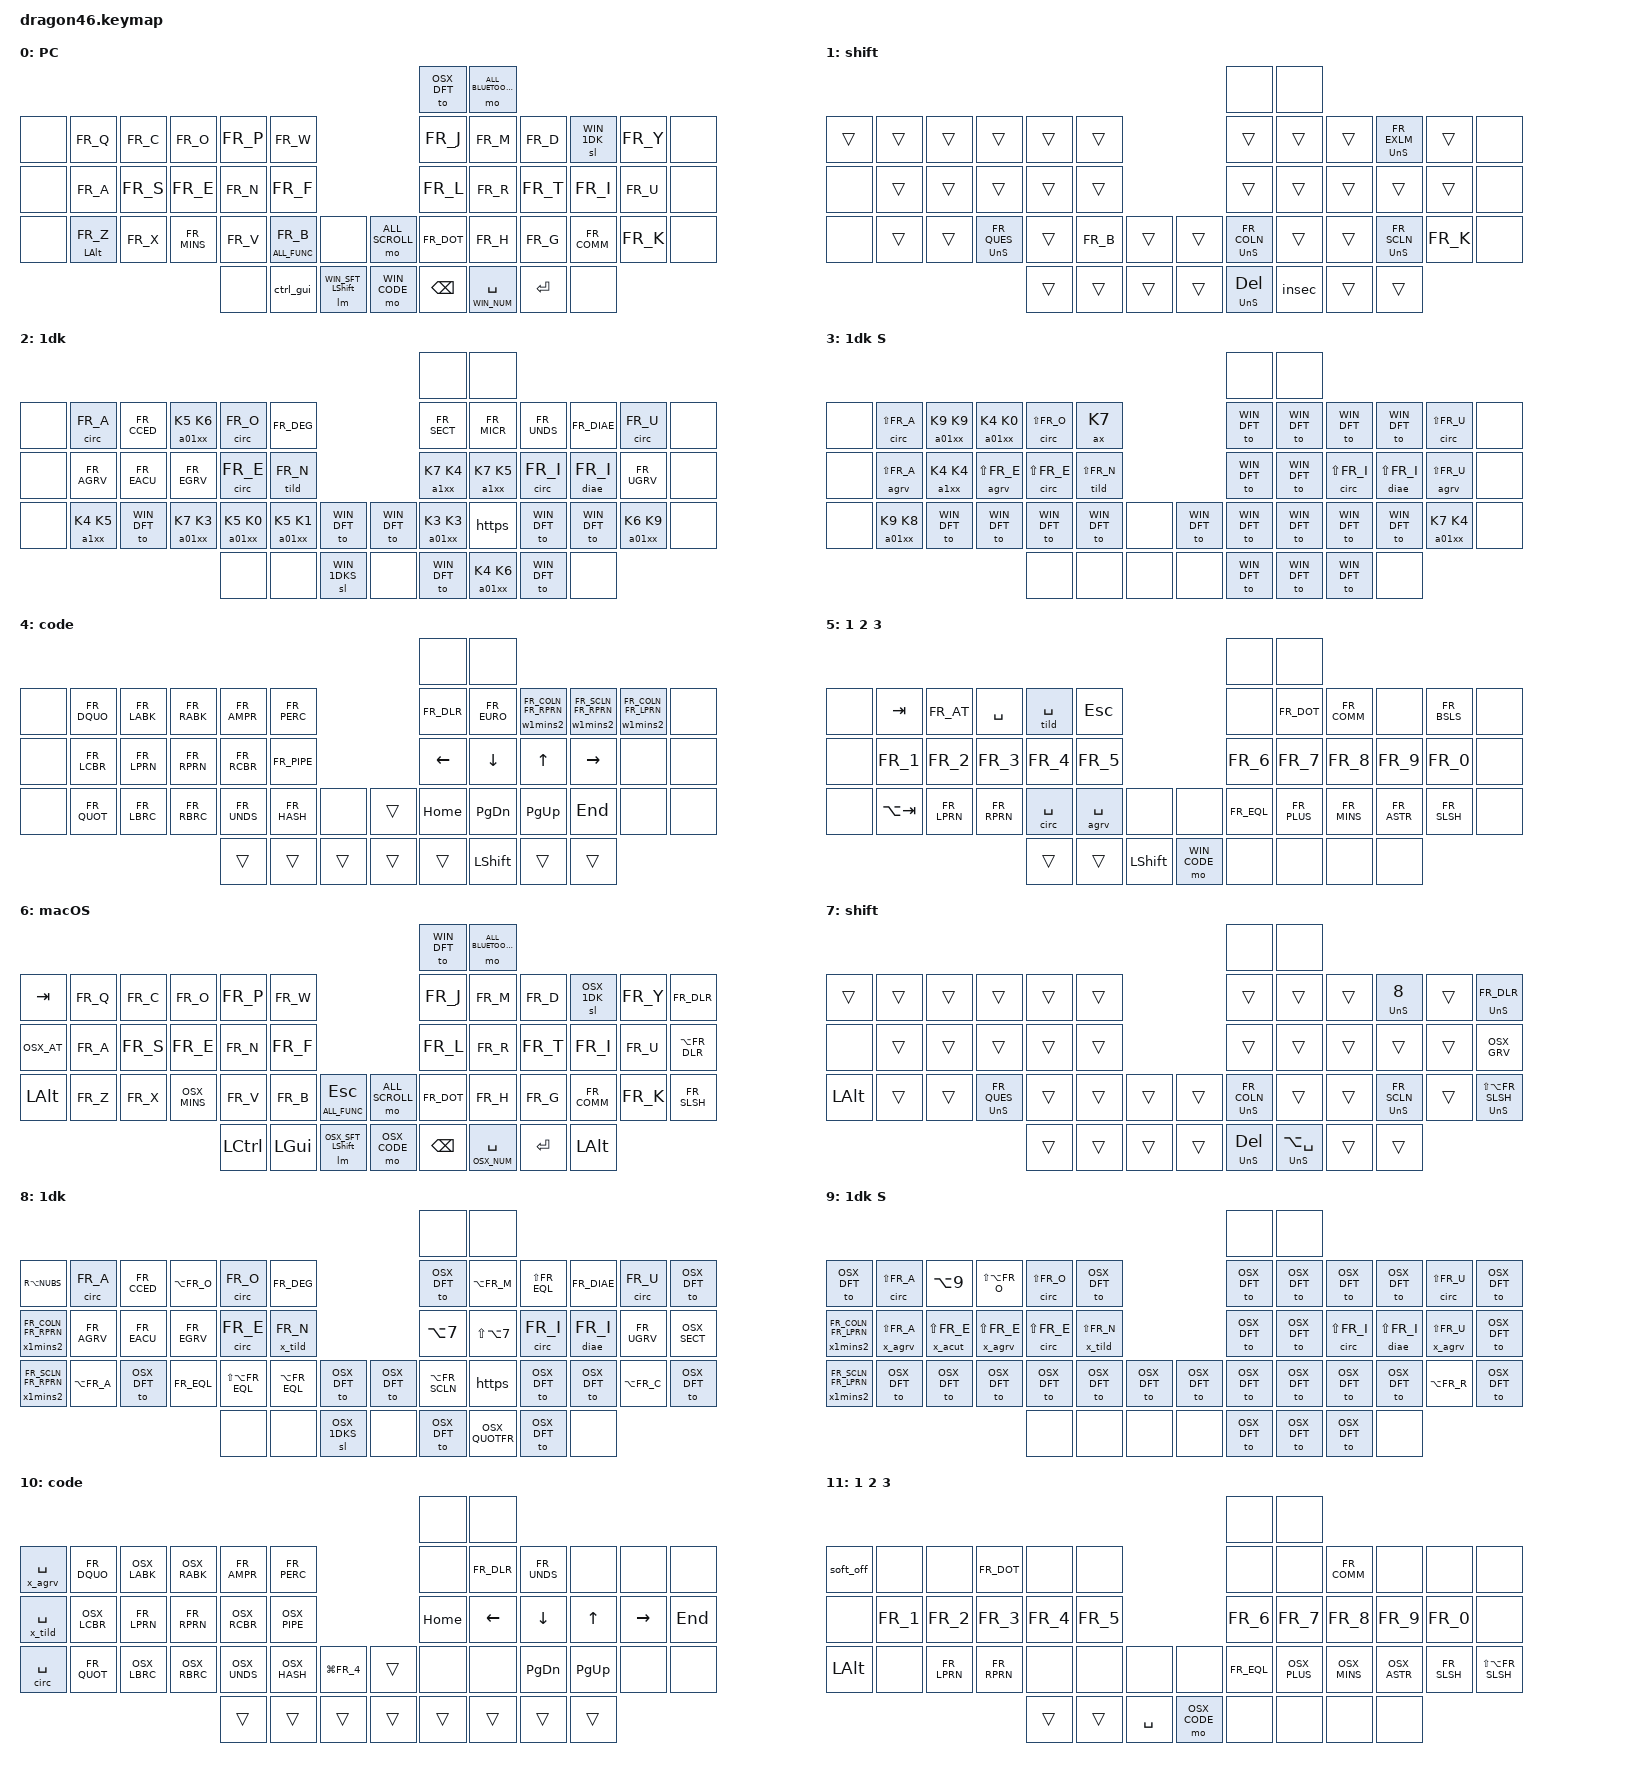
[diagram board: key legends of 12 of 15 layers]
/*
 * Copyright (c) 2021 The ZMK Contributors
 *
 * SPDX-License-Identifier: MIT
 */

 /* COMPIL:
west build -b nice_nano_v2 -- -DSHIELD="dragon46 nice_view_adapter nice_view" 
 */

#include <behaviors.dtsi>
#include <dt-bindings/zmk/keys.h>
#include <dt-bindings/zmk/bt.h>
#include <dt-bindings/zmk/outputs.h>
#include <dt-bindings/zmk/ext_power.h>
#include "keymap_french.h"

#define WIN_DFT         0
#define WIN_SFT         1
#define WIN_1DK         2
#define WIN_1DKS        3
#define WIN_CODE        4
#define WIN_NUM         5

#define OSX_DFT         6
#define OSX_SFT         7
#define OSX_1DK         8
#define OSX_1DKS        9
#define OSX_CODE        10
#define OSX_NUM         11

#define ALL_FUNC        12
#define ALL_SCROLL      13
#define ALL_BLUETOOTH   14

#define K0 KP_N0
#define K1 KP_N1
#define K2 KP_N2
#define K3 KP_N3
#define K4 KP_N4
#define K5 KP_N5
#define K6 KP_N6
#define K7 KP_N7
#define K8 KP_N8
#define K9 KP_N9 

&sl {
    release-after-ms = <2000>;
};

/ {

    macros {
        lm: lm {
            compatible = "zmk,behavior-macro-two-param";
            wait-ms = <0>;
            tap-ms = <0>;
            #binding-cells = <2>;
            bindings
                = <&macro_param_1to1>
                , <&macro_press &mo MACRO_PLACEHOLDER>
                , <&macro_param_2to1>
                , <&macro_press &kp MACRO_PLACEHOLDER>
                , <&macro_pause_for_release>
                , <&macro_param_2to1>
                , <&macro_release &kp MACRO_PLACEHOLDER>
                , <&macro_param_1to1>
                , <&macro_release &mo MACRO_PLACEHOLDER>
                ;
        };

        ctrl_gui: tap_dance_mod_tap {
            compatible = "zmk,behavior-tap-dance";
            #binding-cells = <0>;
            tapping-term-ms = <200>;
            bindings = <&kp LCTRL>, <&kp LGUI>;
        };

        UnS: UnS {
            compatible = "zmk,behavior-macro-one-param";
            #binding-cells = <1>;
            bindings = 
                <&macro_release &kp LSHFT>
                ,<&macro_param_1to1>,<&macro_tap &kp MACRO_PLACEHOLDER>
                ,<&macro_press &kp LSHFT>;
        };

        circ: circ {
            compatible = "zmk,behavior-macro-one-param";
            #binding-cells = <1>;
            wait-ms = <20>;
            tap-ms = <20>;
            bindings = 
                <&macro_tap &kp FR_CIRC>
                ,<&macro_param_1to1>,<&macro_tap &kp MACRO_PLACEHOLDER>;
        };

        tild: tild {
            compatible = "zmk,behavior-macro-one-param";
            #binding-cells = <1>;
            wait-ms = <20>;
            tap-ms = <20>;
            bindings = 
                <&macro_tap &kp FR_TILD>
                ,<&macro_param_1to1>,<&macro_tap &kp MACRO_PLACEHOLDER>;
        };

        x_tild: x_tild {
            compatible = "zmk,behavior-macro-one-param";
            #binding-cells = <1>;
            wait-ms = <20>;
            tap-ms = <20>;
            bindings = 
                <&macro_tap &kp LA(FR_N)>
                ,<&macro_param_1to1>,<&macro_tap &kp MACRO_PLACEHOLDER>;
        };

        diae: diae {
            compatible = "zmk,behavior-macro-one-param";
            #binding-cells = <1>;
            wait-ms = <20>; tap-ms = <20>;
            bindings = 
                <&macro_tap &kp LS(FR_CIRC)>
                ,<&macro_param_1to1>,<&macro_tap &kp MACRO_PLACEHOLDER>;
        };

        caps: caps {
            compatible = "zmk,behavior-macro-one-param";
            #binding-cells = <1>;
            wait-ms = <40>; tap-ms = <40>;
            bindings = 
                <&macro_tap &kp CAPS>
                ,<&macro_param_1to1>,<&macro_tap &kp MACRO_PLACEHOLDER>
                ,<&macro_tap &kp CAPS>;
        };

        x_acut: x_acut {
            compatible = "zmk,behavior-macro-one-param";
            #binding-cells = <1>;
            wait-ms = <20>; tap-ms = <20>;
            bindings = 
                <&macro_tap &kp LS(LA(N1))>
                ,<&macro_param_1to1>,<&macro_tap &kp MACRO_PLACEHOLDER>;
        };

        x_agrv: x_agrv {
            compatible = "zmk,behavior-macro-one-param";
            #binding-cells = <1>;
            wait-ms = <20>; tap-ms = <20>;
            bindings = 
                <&macro_tap &kp OSX_GRV>
                ,<&macro_param_1to1>,<&macro_tap &kp MACRO_PLACEHOLDER>;
        };

        agrv: agrv {
            compatible = "zmk,behavior-macro-one-param";
            #binding-cells = <1>;
            wait-ms = <20>; tap-ms = <20>;
            bindings = 
                <&macro_tap &kp FR_GRV>
                ,<&macro_param_1to1>,<&macro_tap &kp MACRO_PLACEHOLDER>;
        };

        ax: ax {
            compatible = "zmk,behavior-macro-one-param";
            #binding-cells = <1>;
            wait-ms = <20>; tap-ms = <20>;
            bindings = 
                <&macro_press &kp LALT>
                ,<&macro_param_1to1>,<&macro_tap &kp MACRO_PLACEHOLDER>
                ,<&macro_release &kp LALT>;
        };

        a1xx: a1xx {
            compatible = "zmk,behavior-macro-two-param";
            #binding-cells = <2>;
            wait-ms = <20>; tap-ms = <20>;
            bindings = 
                <&macro_press &kp LALT>
                ,<&macro_tap &kp KP_N1>
                ,<&macro_param_1to1>,<&macro_tap &kp MACRO_PLACEHOLDER>
                ,<&macro_param_2to1>,<&macro_tap &kp MACRO_PLACEHOLDER>
                ,<&macro_release &kp LALT>;
        };

        a2xx: a2xx {
            compatible = "zmk,behavior-macro-two-param";
            #binding-cells = <2>;
            wait-ms = <20>; tap-ms = <20>;
            bindings = 
                <&macro_press &kp LALT>
                ,<&macro_tap &kp KP_N2>
                ,<&macro_param_1to1>,<&macro_tap &kp MACRO_PLACEHOLDER>
                ,<&macro_param_2to1>,<&macro_tap &kp MACRO_PLACEHOLDER>
                ,<&macro_release &kp LALT>;
        };

        a01xx: a01xx {
            compatible = "zmk,behavior-macro-two-param";
            #binding-cells = <2>;
            wait-ms = <10>; tap-ms = <10>;
            bindings = 
                <&macro_press &kp LALT>
                ,<&macro_tap &kp KP_N0>
                ,<&macro_tap &kp KP_N1>
                ,<&macro_param_1to1>,<&macro_tap &kp MACRO_PLACEHOLDER>
                ,<&macro_param_2to1>,<&macro_tap &kp MACRO_PLACEHOLDER>
                ,<&macro_release &kp LALT>;
        };

        insec: insec {
            compatible = "zmk,behavior-macro";
            #binding-cells = <0>;
            wait-ms = <20>; tap-ms = <20>;
            bindings = 
                <&macro_release &kp LSHFT>
                ,<&macro_press &kp LALT>
                ,<&macro_tap &kp KP_N0>,<&macro_tap &kp KP_N1>,<&macro_tap &kp KP_N6>,<&macro_tap &kp KP_N0>
                ,<&macro_release &kp LALT>
                ,<&macro_press &kp LSHFT>;
        };

/* BT */

        bt_prof0: bt_prof0 {
            compatible = "zmk,behavior-macro";
            #binding-cells = <0>;
            bindings = 
                <&macro_press &bt BT_SEL 0>
                ,<&macro_press &to WIN_DFT>;
        };

        bt_prof1: bt_prof1 {
            compatible = "zmk,behavior-macro";
            #binding-cells = <0>;
            bindings = 
                <&macro_press &bt BT_SEL 1>
                ,<&macro_press &to OSX_DFT>;
        };

        bt_prof2: bt_prof2 {
            compatible = "zmk,behavior-macro";
            #binding-cells = <0>;
            bindings = 
                <&macro_press &bt BT_SEL 2>
                ,<&macro_press &to WIN_DFT>;
        };

/* SEQUENCES */
        w1mins2: w1mins2 {
            compatible = "zmk,behavior-macro-two-param";
            #binding-cells = <2>;
            wait-ms = <20>; tap-ms = <20>;
            bindings = 
                <&macro_param_1to1>,<&macro_tap &kp MACRO_PLACEHOLDER>,
                <&macro_tap &kp FR_MINS>,
                <&macro_param_2to1>,<&macro_tap &kp MACRO_PLACEHOLDER>;
        };

        x1mins2: x1mins2 {
            compatible = "zmk,behavior-macro-two-param";
            #binding-cells = <2>;
            wait-ms = <20>; tap-ms = <20>;
            bindings = 
                <&macro_param_1to1>,<&macro_tap &kp MACRO_PLACEHOLDER>,
                <&macro_tap &kp OSX_MINS>,
                <&macro_param_2to1>,<&macro_tap &kp MACRO_PLACEHOLDER>;
        };

        https: https {
            compatible = "zmk,behavior-macro";
            #binding-cells = <0>;
            bindings = 
                <&macro_tap &kp FR_H>,
                <&macro_tap &kp FR_T>,
                <&macro_tap &kp FR_T>,
                <&macro_tap &kp FR_P>,
                <&macro_tap &kp FR_S>,
                <&macro_tap &kp FR_COLN>,
                <&macro_tap &kp FR_SLSH>,
                <&macro_tap &kp FR_SLSH>;
        };

        
    };
    
    keymap {
        compatible = "zmk,keymap";

// ****************************** WINDOWS ****************************************
        win_default_layer {
            bindings = <
                                                        /*&soft_off*/                                             &to OSX_DFT  &mo ALL_BLUETOOTH
&none            &kp FR_Q      &kp FR_C    &kp FR_O     &kp FR_P     &kp FR_W                                     &kp FR_J     &kp FR_M     &kp FR_D     &sl WIN_1DK  &kp FR_Y     &none
&none            &kp FR_A      &kp FR_S    &kp FR_E     &kp FR_N     &kp FR_F                                     &kp FR_L     &kp FR_R     &kp FR_T     &kp FR_I     &kp FR_U     &none
&none            &mt LALT FR_Z &kp FR_X    &kp FR_MINS  &kp FR_V     &lt ALL_FUNC FR_B   &none     &mo ALL_SCROLL &kp FR_DOT   &kp FR_H     &kp FR_G     &kp FR_COMM  &kp FR_K     &none
                                                   &none &ctrl_gui &lm WIN_SFT LSHIFT &mo WIN_CODE &kp BSPC       &lt WIN_NUM SPACE &kp RET &none    
            >;
            sensor-bindings = <&inc_dec_kp UP DOWN>;
            display-name = "PC";
        };

        win_shift_layer {
            bindings = <
                                                /*&none*/                                            &none          &none
&trans      &trans       &trans     &trans       &trans      &trans                                  &trans         &trans       &trans     &UnS FR_EXLM &trans      &none
&none       &trans       &trans     &trans       &trans      &trans                                  &trans         &trans       &trans     &trans       &trans      &none
&none       &trans       &trans     &UnS FR_QUES &trans      &kp FR_B    &trans          &trans      &UnS FR_COLN   &trans       &trans     &UnS FR_SCLN &kp FR_K    &none
                                    &trans       &trans      &trans      &trans          &UnS DEL    &insec         &trans       &trans    
            >;
            sensor-bindings = <&inc_dec_kp UP DOWN>;
            display-name = "shift";
        };

        win_1dk_layer {
            bindings = <
                                                        /*&none*/                                             &none           &none
/* +------------------------+------------+-----------+-------------+-------------+-----------+                          +-------------+------------+-----------+-----------+-------------+-----------+*/
/* |                        |      â     |     ç     |alt+0156=œ   |      ô      |     °     |                          |             |    µ       |      _    |   ¨(dead) |       û     |           |*/
    &none                    &circ FR_A   &kp FR_CCED &a01xx K5 K6  &circ FR_O    &kp FR_DEG                             &kp FR_SECT  &kp FR_MICR  &kp FR_UNDS &kp FR_DIAE &circ FR_U     &none  
/* +------------------------+------------+-----------+-------------+-------------+-----------+                          +-------------+------------+-----------+-----------+-------------+-----------+*/
/*                          |    à       |  é        |  è          |    ê        |      ñ                               |alt+174 = «  | alt+175 = »|      î    |      ï    |    ù        |           |*/
  &none                      &kp FR_AGRV  &kp FR_EACU &kp FR_EGRV   &circ FR_E    &tild FR_N                             &a1xx K7 K4   &a1xx K7 K5  &circ FR_I  &diae FR_I  &kp FR_UGRV   &none
/* +------------------------+------------+-----------+-------------+-------------+-----------+----------+    +----------+-------------+------------+-----------+-----------+-------------+-----------+*/
/*                          |alt+145 = æ |           |alt+0173=-(d)|alt+0150=–   |alt+0151=— |          |    |          |alt+0133=…   |            |           |            alt+0169=©                */
  &none                      &a1xx K4 K5 &to WIN_DFT  &a01xx K7 K3  &a01xx K5 K0 &a01xx K5 K1 &to WIN_DFT    &to WIN_DFT &a01xx K3 K3  &https       &to WIN_DFT &to WIN_DFT &a01xx K6 K9  &none  
/* +------------------------+------------+-----------+-------------+-------------+-----------+----------+    +----------+-------------+------------+-----------+-----------+-------------+-----------+*/
/*                                                   |             |             |           |          |    |          | alt+0146=’  |            |           |                                      */
                                                        &none         &none     &sl WIN_1DKS &none           &to WIN_DFT &a01xx K4 K6  &to WIN_DFT  &none 
/*                                                   +-------------+-------------+-----------+----------+    +----------+-------------+------------+-----------+                                      */
            >;
            sensor-bindings = <&inc_dec_kp UP DOWN>;
            display-name = "1dk";
        };

        win_1dks_layer {
            bindings = <
                                                        /*&none*/                                                   &none        &none
// +----------------------+--------------+-----------+--------------+--------------+--------------+                          +------------+------------+--------------+--------------+----------------+-----------+
// |                      |      Â       | alt+0199=Ç | alt+0140=Œ   |      Ô       |  alt+7=•     |                          |            |            |              |              |       Û        |           |
  &none                    &circ LS(FR_A) &a01xx K9 K9 &a01xx K4 K0  &circ LS(FR_O)  &ax K7                                   &to WIN_DFT  &to WIN_DFT  &to WIN_DFT    &to WIN_DFT      &circ LS(FR_U)  &none  
// +----------------------+--------------+-----------+--------------+--------------+--------------+                          +------------+------------+--------------+--------------+----------------+-----------+
// |                      |alt+183 = À   | alt+144=É | alt+212 = È  |      Ê       |     Ñ        |                          |            |            |      Î       |      Ï       |       Û        |           |
  &none                    &agrv LS(FR_A) &a1xx K4 K4 &agrv LS(FR_E) &circ LS(FR_E) &tild LS(FR_N)                            &to WIN_DFT  &to WIN_DFT  &circ LS(FR_I) &diae LS(FR_I) &agrv LS(FR_U)   &none  
// +----------------------+--------------+-----------+--------------+--------------+--------------+----------+    +----------+------------+------------+--------------+--------------+----------------+-----------+
// |                      |alt+0198=Æ    |           |              |              |              |          |    |          |            |            |              |              | alt+0174 = (r) |           |
  &none                    &a01xx K9 K8   &to WIN_DFT &to WIN_DFT    &to WIN_DFT    &to WIN_DFT   &none           &to WIN_DFT &to WIN_DFT  &to WIN_DFT  &to WIN_DFT    &to WIN_DFT     &a01xx K7 K4    &none  
// +----------------------+--------------+-----------+--------------+--------------+--------------+----------+    +----------+------------+------------+--------------+--------------+----------------+-----------+
//                                                   |              |             |               |          |    |          |            |            |              |                                            
                                                       &none            &none          &none        &none           &to WIN_DFT &to WIN_DFT  &to WIN_DFT  &none   
//                                                   +--------------+-------------+---------------+----------+    +----------+------------+------------+--------------+                                                                                      
            >;
            sensor-bindings = <&inc_dec_kp UP DOWN>;
            display-name = "1dk S";
        };

        win_code_layer {
            bindings = <
                                                        /*&none*/                                     &none       &none
&none   &kp FR_DQUO  &kp FR_LABK  &kp FR_RABK  &kp FR_AMPR   &kp FR_PERC                        &kp FR_DLR  &kp FR_EURO &w1mins2 FR_COLN FR_RPRN &w1mins2 FR_SCLN FR_RPRN &w1mins2 FR_COLN FR_LPRN &none
&none   &kp FR_LCBR  &kp FR_LPRN  &kp FR_RPRN  &kp FR_RCBR   &kp FR_PIPE                        &kp LEFT    &kp DOWN    &kp UP     &kp RIGHT   &none       &none
&none   &kp FR_QUOT  &kp FR_LBRC  &kp FR_RBRC  &kp FR_UNDS   &kp FR_HASH  &none       &trans    &kp HOME    &kp PG_DN   &kp PG_UP  &kp END     &none       &none
                                     &trans      &trans      &trans       &trans      &trans    &kp LSHIFT  &trans  &trans    
            >;
            sensor-bindings = <&inc_dec_kp LEFT RIGHT>;
            display-name = "code";
        };

        win_num_layer {
            bindings = <
                            /*&none*/                                                           &none       &none
&none       &kp TAB     &kp FR_AT   &kp SPACE    &tild SPACE  &kp ESC                           &none       &kp FR_DOT  &kp FR_COMM  &none       &kp FR_BSLS &none
&none       &kp FR_1    &kp FR_2    &kp FR_3     &kp FR_4     &kp FR_5                          &kp FR_6    &kp FR_7    &kp FR_8     &kp FR_9    &kp FR_0    &none
&none       &kp LA(TAB) &kp FR_LPRN &kp FR_RPRN  &circ SPACE  &agrv SPACE &none        &none    &kp FR_EQL  &kp FR_PLUS &kp FR_MINS  &kp FR_ASTR &kp FR_SLSH &none 
                                    &trans       &trans       &kp LSHIFT  &mo WIN_CODE &none    &none       &none       &none    
            >;
            sensor-bindings = <&inc_dec_kp UP DOWN>;
            display-name = "1 2 3";
        };

// ****************************** APPLE ****************************************
        osx_default_layer {
            bindings = <
                                                        /*&soft_off*/                                              &to WIN_DFT  &mo ALL_BLUETOOTH
&kp TAB           &kp FR_Q      &kp FR_C    &kp FR_O     &kp FR_P     &kp FR_W                                     &kp FR_J     &kp FR_M     &kp FR_D     &sl OSX_1DK  &kp FR_Y     &kp FR_DLR
&kp OSX_AT        &kp FR_A      &kp FR_S    &kp FR_E     &kp FR_N     &kp FR_F                                     &kp FR_L     &kp FR_R     &kp FR_T     &kp FR_I     &kp FR_U     &kp LA(FR_DLR)
&kp LALT          &kp FR_Z      &kp FR_X    &kp OSX_MINS &kp FR_V     &kp FR_B &lt ALL_FUNC ESC     &mo ALL_SCROLL &kp FR_DOT   &kp FR_H     &kp FR_G     &kp FR_COMM  &kp FR_K     &kp FR_SLSH
                                            &kp LCTRL &kp LGUI &lm OSX_SFT LSHIFT &mo OSX_CODE      &kp BSPC       &lt OSX_NUM SPACE &kp RET &kp LALT    
            >;
            sensor-bindings = <&inc_dec_kp UP DOWN>;
            display-name = "macOS";
        };

        osx_shift_layer {
            bindings = <
                                                    /*&none*/                                            &none          &none
&trans      &trans       &trans     &trans       &trans      &trans                                  &trans         &trans       &trans     &UnS N8      &trans      &UnS FR_DLR
&none       &trans       &trans     &trans       &trans      &trans                                  &trans         &trans       &trans     &trans       &trans      &kp OSX_GRV
&kp LALT    &trans       &trans     &UnS FR_QUES &trans      &trans      &trans          &trans      &UnS FR_COLN   &trans       &trans     &UnS FR_SCLN &trans      &UnS LS(LA(FR_SLSH))
                                    &trans       &trans      &trans      &trans          &UnS DEL    &UnS LA(SPACE) &trans       &trans    
            >;
            sensor-bindings = <&inc_dec_kp UP DOWN>;
            display-name = "shift";
        };

        osx_1dk_layer {
            bindings = <
                                                    /*&none*/                                                      &none           &none
&kp RA(NUBS)             &circ FR_A   &kp FR_CCED &kp LA(FR_O) &circ FR_O         &kp FR_DEG                                 &to OSX_DFT     &kp LA(FR_M)      &kp LS(FR_EQL) &kp FR_DIAE   &circ FR_U    &to OSX_DFT  
&x1mins2 FR_COLN FR_RPRN &kp FR_AGRV  &kp FR_EACU &kp FR_EGRV  &circ FR_E         &x_tild FR_N                               &kp LA(N7)      &kp LS(LA(N7))    &circ FR_I     &diae FR_I    &kp FR_UGRV   &kp OSX_SECT
&x1mins2 FR_SCLN FR_RPRN &kp LA(FR_A) &to OSX_DFT &kp FR_EQL   &kp LS(LA(FR_EQL)) &kp LA(FR_EQL) &to OSX_DFT     &to OSX_DFT &kp LA(FR_SCLN) &https            &to OSX_DFT    &to OSX_DFT   &kp LA(FR_C)  &to OSX_DFT  
                                        &none        &none             &sl OSX_1DKS   &none      &to OSX_DFT   &kp OSX_QUOTFR &to OSX_DFT    &none 
            >;
            sensor-bindings = <&inc_dec_kp UP DOWN>;
            display-name = "1dk";
        };

        osx_1dks_layer {
            bindings = <
                                                /*&none*/                                                                       &none       &none
&to OSX_DFT              &circ LS(FR_A)   &kp LA(N9)       &kp LS(LA(FR_O)) &circ LS(FR_O) &to OSX_DFT                                      &to OSX_DFT  &to OSX_DFT  &to OSX_DFT    &to OSX_DFT    &circ LS(FR_U)   &to OSX_DFT  
&x1mins2 FR_COLN FR_LPRN &x_agrv LS(FR_A) &x_acut LS(FR_E) &x_agrv LS(FR_E) &circ LS(FR_E) &x_tild LS(FR_N)                                 &to OSX_DFT  &to OSX_DFT  &circ LS(FR_I) &diae LS(FR_I) &x_agrv LS(FR_U) &to OSX_DFT  
&x1mins2 FR_SCLN FR_LPRN &to OSX_DFT      &to OSX_DFT      &to OSX_DFT      &to OSX_DFT    &to OSX_DFT      &to OSX_DFT         &to OSX_DFT &to OSX_DFT  &to OSX_DFT  &to OSX_DFT    &to OSX_DFT    &kp LA(FR_R)     &to OSX_DFT  
                                                            &none            &none          &none            &none               &to OSX_DFT &to OSX_DFT  &to OSX_DFT  &none     
            >;
            sensor-bindings = <&inc_dec_kp UP DOWN>;
            display-name = "1dk S";
        };

        osx_code_layer {
            bindings = <
                                                        /*&none*/                                           &none       &none
&x_agrv SPACE &kp FR_DQUO     &kp OSX_LABK &kp OSX_RABK &kp FR_AMPR  &kp FR_PERC                               &none       &kp FR_DLR &kp FR_UNDS &none      &none       &none
&x_tild SPACE &kp OSX_LCBR &kp FR_LPRN  &kp FR_RPRN  &kp OSX_RCBR &kp OSX_PIPE                              &kp HOME    &kp LEFT   &kp DOWN    &kp UP     &kp RIGHT   &kp END
&circ SPACE   &kp FR_QUOT  &kp OSX_LBRC &kp OSX_RBRC &kp OSX_UNDS &kp OSX_HASH  &kp LG(FR_4)      &trans    &none       &none      &kp PG_DN   &kp PG_UP  &none       &none
                                        &trans       &trans       &trans        &trans            &trans    &trans      &trans     &trans    
            >;
            sensor-bindings = <&inc_dec_kp LEFT RIGHT>;
            display-name = "code";
        };

        osx_num_layer {
            bindings = <
                            /*&none*/                                                           &none       &none
&soft_off   &none       &none       &kp FR_DOT   &none        &none                             &none       &none        &kp FR_COMM   &none        &none       &none
&none       &kp FR_1    &kp FR_2    &kp FR_3     &kp FR_4     &kp FR_5                          &kp FR_6    &kp FR_7     &kp FR_8      &kp FR_9     &kp FR_0    &none
&kp LALT    &none       &kp FR_LPRN &kp FR_RPRN  &none        &none     &none        &none      &kp FR_EQL  &kp OSX_PLUS &kp OSX_MINS  &kp OSX_ASTR &kp FR_SLSH &kp LS(LA(FR_SLSH)) 
                                    &trans       &trans       &kp SPACE &mo OSX_CODE &none      &none       &none        &none    
            >;
            sensor-bindings = <&inc_dec_kp UP DOWN>;
            display-name = "1 2 3";
        };

// ****************************** COMMON ****************************************
//        nav_layer {
//            bindings = <
//                            /*&none*/                              &none     &none
//&soft_off   &none &none &none  &none  &none                       &none    &none    &none     &none     &none     &none
//&none       &none &none &none  &none  &none                       &kp HOME &kp LEFT &kp DOWN  &kp UP    &kp RIGHT &kp END
//&kp LALT    &none &none &none  &none  &none     &none       &none &none    &none    &kp PG_DN &kp PG_UP &none     &none 
//                        &trans &trans &kp LSHFT &none       &none &none    &none    &none    
//            >;
//            sensor-bindings = <&inc_dec_kp UP DOWN>;
//            display-name = "nav";
//        };


        func_layer {
            bindings = <
                            /*&none*/                                      &none         &none
&none       &sys_reset  &none &none  &kp C_BRI_UP &kp C_VOL_UP                          &kp F1  &kp F2  &kp F3  &kp F4  &kp F5  &none  
&none       &bootloader &none &none  &kp C_BRI_DN &kp C_VOL_DN                          &kp F6  &kp F7  &kp F8  &kp F9  &kp F10 &none 
&none       &none       &none &none  &none        &none         &none        &kp C_MUTE &kp F11 &kp F12 &none   &none   &none   &none         
                                &trans &trans &kp LSHFT &kp LC(LA(DEL))      &kp C_MUTE &kp LG(F4)  &none   &trans     
            >;
            sensor-bindings = <&inc_dec_kp C_VOL_UP C_VOL_DN>;
            display-name = "func";
        };

        scroll_layer {
            bindings = <
                                                /*&none*/                                               &none       &none
&trans      &trans       &trans     &trans      &trans      &trans                                  &trans      &trans       &trans     &trans      &trans      &trans
&trans      &trans       &trans     &trans      &trans      &trans                                  &trans      &trans       &trans     &trans      &trans      &trans
&trans      &trans       &trans     &trans      &trans      &trans      &trans          &trans      &trans      &trans       &trans     &trans      &trans      &trans
                                    &trans      &trans      &kp LSHFT   &trans          &trans      &trans      &trans       &trans    
            >;
            sensor-bindings = <&inc_dec_kp PG_UP PG_DN>;
            display-name = "scroll";
        };

        bluetooth_layer {
            bindings = <
                            /*&none*/                                            &bt BT_CLR &trans
&none   &none     &none     &none      &none        &out OUT_BLE                 &none      &none   &none &none &none &none
&none   &bt_prof0 &bt_prof1 &bt_prof2  &bt BT_SEL 3 &bt BT_SEL 4                 &none      &none   &none &none &none &none
&none   &none     &none     &none      &none        &out OUT_USB &none    &none  &none      &none   &none &none &none &none 
                            &none      &none        &none        &none    &none  &none      &none   &none    
            >;
            sensor-bindings = <&inc_dec_kp UP DOWN>;
            display-name = "bluetooth";
        };


    };
};
